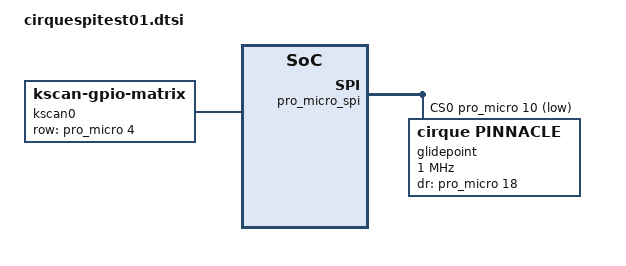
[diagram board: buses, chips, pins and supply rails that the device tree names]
/*
 * Copyright (c) 2020 The ZMK Contributors
 *
 * SPDX-License-Identifier: MIT
 */

#include <dt-bindings/zmk/matrix_transform.h>
#include <dt-bindings/zmk/input_transform.h>
#include <input/processors.dtsi>

/ {
    chosen {
        zmk,kscan = &kscan0;
        zmk,matrix_transform = &default_transform;
    };

    default_transform: keymap_transform_0 {
        compatible = "zmk,matrix-transform";
        columns = <3>;
        rows = <1>;
        map = <
            RC(0,0) RC(0,1) RC(0,2)
        >;
    };

    kscan0: kscan {
        compatible = "zmk,kscan-gpio-matrix";
        wakeup-source;

        diode-direction = "col2row";
        row-gpios
            = <&pro_micro 4 (GPIO_ACTIVE_HIGH | GPIO_PULL_DOWN)>
            ;
    };

    glidepoint_listener: glidepoint_listener {
        compatible = "zmk,input-listener";
        status = "disabled";
        device = <&glidepoint>;
    };
};

&pro_micro_spi {
    status = "okay";
    cs-gpios = <&pro_micro 10 GPIO_ACTIVE_LOW>;

    glidepoint: glidepoint@0 {
        compatible = "cirque,pinnacle";
        reg = <0>;
        spi-max-frequency = <1000000>;
        status = "okay";
        dr-gpios = <&pro_micro 18 (GPIO_ACTIVE_HIGH)>;

        sensitivity = "4x";
        //sleep;
        no-taps;
    };
};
